# Template register map
Vendor: VendorName Co.Ltd; Series: SeriesName; File version: 1.2
CPU: CM7 r0p1, little endian, MPU, FPU, 4 interrupt priority bits
Registers are 32-bit, read-write, no defined reset value unless marked. A register's access mark holds for its fields unless they carry their own. Offsets are from the block's base; [hi:lo] are bit positions.

## UART1 — Universal Asynchronous Receiver Or Transmitter 1
Base 0x40042000
Same registers: UART2 0x40043000, UART3 0x40060000, UART4 0x40061000
0x08 GLOBAL — UART global register
  [1] RST — UART RST bit: software reset
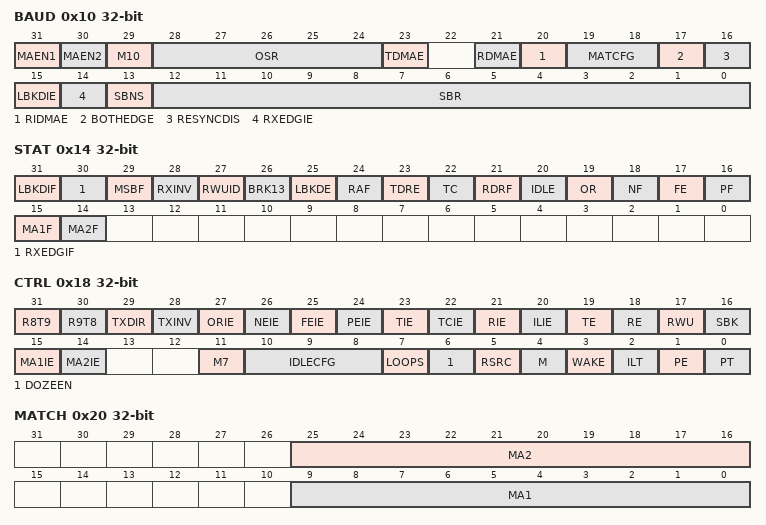
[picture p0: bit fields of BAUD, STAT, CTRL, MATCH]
0x10 BAUD — UART baudrate register
  [31] MAEN1 — UART MAEN1 bit: match address mode enable 1
  [30] MAEN2 — UART MAEN2 bit: match address mode enable 2
  [29] M10 — UART M10 bit: 10-bit mode select
  [28:24] OSR — UART OSR[4:0] bit: oversampling ratio
  [23] TDMAE — UART TDMAE bit: transmitter DMA enable
  [21] RDMAE — UART RDMAE bit: receiver full DMA enable
  [20] RIDMAE — UART RIDMAE bit: receiver idle DMA enable
  [19:18] MATCFG — UART MATCFG[1:0] bit: match configuration
  [17] BOTHEDGE — UART BOTHEDGE bit: both edge sampling
  [16] RESYNCDIS — UART RESYNCDIS bit: resynchronization disable
  [15] LBKDIE — UART LBKDIE bit: LIN break detect interrupt enable
  [14] RXEDGIE — UART RXEDGIE bit: RX input active edge interrupt enable
  [13] SBNS — UART SBNS bit: stop bit number select
  [12:0] SBR — UART SBR[12:0] bit: baud rate modulo divisor
0x14 STAT — UART state register
  [31] LBKDIF — UART LBKDIF bit: LIN break detect interrupt flag
  [30] RXEDGIF — UART RXEDGIF bit: RXD pin active edge interrupt flag
  [29] MSBF — UART MSBF bit: MSB first
  [28] RXINV — UART RXINV bit: receive data inversion
  [27] RWUID — UART RWUID bit: receive wake up idle detect
  [26] BRK13 — UART BRK13 bit: break character generation length
  [25] LBKDE — UART LBKDE bit: LIN break detection enable
  [24] RAF ro — UART RAF bit: receiver active flag
  [23] TDRE ro — UART TDRE bit: transmit data register empty flag
  [22] TC ro — UART TC bit: transmission complete flag
  [21] RDRF ro — UART RDRF bit: receive data register full flag
  [20] IDLE — UART IDLE bit: idle line flag
  [19] OR — UART OR bit: receiver overrun flag
  [18] NF — UART NF bit: noise flag
  [17] FE — UART FE bit: framing error flag
  [16] PF — UART PF bit: parity error flag
  [15] MA1F — UART MA1F bit: match 1 flag
  [14] MA2F — UART MA2F bit: match 2 flag
0x18 CTRL — UART control register
  [31] R8T9 — UART R8T9 bit: receive bit 8 or transmit bit 9
  [30] R9T8 — UART R9T8 bit: receive bit 9 or transmit bit 8
  [29] TXDIR — UART TXDIR bit: TXD pin direction in single-wire mode
  [28] TXINV — UART TXINV bit: transmit data inversion
  [27] ORIE — UART ORIE bit: overrun interrupt enable
  [26] NEIE — UART NEIE bit: noise error interrupt enable
  [25] FEIE — UART FEIE bit: framing error interrupt enable
  [24] PEIE — UART PEIE bit: parity error interrupt enable
  [23] TIE — UART TIE bit: transmit interrupt enable
  [22] TCIE — UART TCIE bit: transmission complete interrupt enable
  [21] RIE — UART RIE bit: receiver interrupt enable
  [20] ILIE — UART ILIE bit: idle line interrupt enable
  [19] TE — UART TE bit: transmitter enable
  [18] RE — UART RE bit: receiver enable
  [17] RWU — UART RWU bit: receiver wakeup control
  [16] SBK — UART SBK bit: send break
  [15] MA1IE — UART MA1IE bit: match 1 interrupt enable
  [14] MA2IE — UART MA2IE bit: match 2 interrupt enable
  [11] M7 — UART M7 bit: 7-bit mode select
  [10:8] IDLECFG — UART IDLECFG[2:0] bit: idle configuration
  [7] LOOPS — UART LOOPS bit: loop mode select
  [6] DOZEEN — UART DOZEEN bit: doze enable
  [5] RSRC — UART RSRC bit: receiver source select
  [4] M — UART M bit: 9-bit or 8-bit mode select
  [3] WAKE — UART WAKE bit: receiver wakeup method select
  [2] ILT — UART ILT bit: idle line type select
  [1] PE — UART PE bit: parity enable
  [0] PT — UART PT bit: parity type
0x20 MATCH — UART address match register
  [25:16] MA2 — UART MA2[9:0] bit: match address 2
  [9:0] MA1 — UART MA1[9:0] bit: match address 1
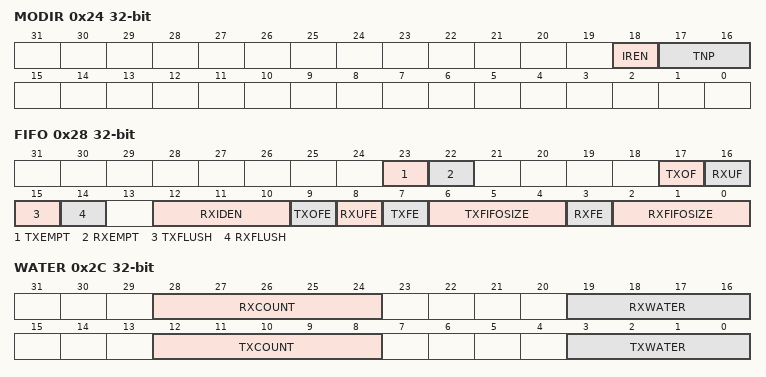
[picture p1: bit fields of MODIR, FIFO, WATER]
0x24 MODIR — UART IrDa mode register
  [18] IREN — UART IREN bit: infrared enable
  [17:16] TNP — UART TNP[1:0] bit: transmitter narrow pulse
0x28 FIFO — UART FIFO register
  [23] TXEMPT ro — UART TXEMPT bit: transmit buffer or FIFO empty
  [22] RXEMPT ro — UART RXEMPT bit: receive buffer or FIFO empty
  [17] TXOF — UART TXOF bit: transmitter buffer overflow flag
  [16] RXUF — UART RXUF bit: receiver buffer underflow flag
  [15] TXFLUSH wo — UART TXFLUSH bit: transmit FIFO or buffer flush
  [14] RXFLUSH wo — UART RXFLUSH bit: receive FIFO or buffer flush
  [12:10] RXIDEN — UART RXIDEN[2:0] bit: receiver idle empty enable
  [9] TXOFE — UART TXOFE bit: transmit FIFO overflow interrupt enable
  [8] RXUFE — UART RXUFE bit: receive FIFO underflow interrupt enable
  [7] TXFE — UART TXFE bit: transmit FIFO enable
  [6:4] TXFIFOSIZE ro — UART TXFIFOSIZE[2:0] bit: transmit FIFO buffer depth
  [3] RXFE — UART RXFE bit: receive FIFO enable
  [2:0] RXFIFOSIZE ro — UART RXFIFOSIZE[2:0] bit: receive FIFO buffer depth
0x2C WATER — UART water level register
  [28:24] RXCOUNT ro — UART RXCOUNT[4:0] bit: receive counter
  [19:16] RXWATER — UART RXWATER[3:0] bit: receive watermark
  [12:8] TXCOUNT ro — UART TXCOUNT[4:0] bit: transmit counter
  [3:0] TXWATER — UART TXWATER[3:0] bit: transmit watermark
